# LPC11D14 register map
File version: 4
CPU: 
Registers are 32-bit, read-write, reset 0x0 unless marked. A register's access mark holds for its fields unless they carry their own. Offsets are from the block's base; [hi:lo] are bit positions; 'fields as' and 'values as' point back to an identical list.

## IOCON — Product name title=UM10398 Chapter title=LPC111x/LPC11Cxx I/O configuration (IOCONFIG) Modification date=9/19/2011 Major revision=7 Minor revision=not available
Base 0x40044000
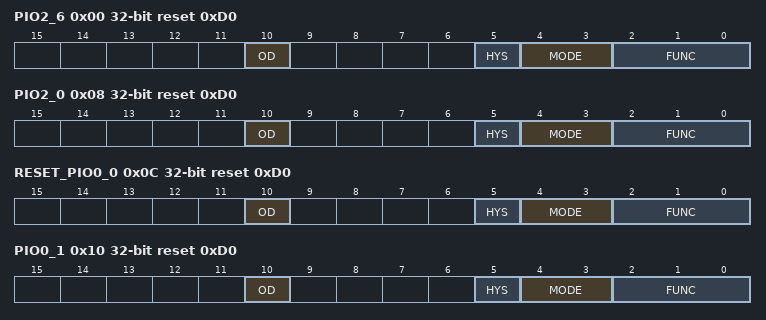
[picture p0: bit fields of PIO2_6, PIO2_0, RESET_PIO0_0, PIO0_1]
0x00 PIO2_6 reset 0xD0 — I/O configuration for pin PIO2_6
  [10] OD — Selects pseudo open-drain mode. See Section 7.1 for part specific details.
    0=STANDARD_GPIO_OUTPUT; 1=OPEN_DRAIN_OUTPUT
  [5] HYS — Hysteresis.
    0=DISABLE_; 1=ENABLE_
  [4:3] MODE — Selects function mode (on-chip pull-up/pull-down resistor control).
    0=INACTIVE_NO_PULL_DO (Inactive (no pull-down/pull-up resistor enabled).); 1=PULL_DOWN_RESISTOR_E (Pull-down resistor enabled.); 2=PULL_UP_RESISTOR_ENA (Pull-up resistor enabled.); 3=REPEATER_MODE_
  [2:0] FUNC — Selects pin function. All other values are reserved.
    0=SELECTS_FUNCTION_PIO (Selects function PIO2_6.)
0x08 PIO2_0 reset 0xD0 — I/O configuration for pin PIO2_0/DTR/SSEL1
  [10] OD — Selects pseudo open-drain mode. See Section 7.1 for part specific details.
    0=STANDARD_GPIO_OUTPUT; 1=OPEN_DRAIN_OUTPUT
  [5] HYS — Hysteresis.
    0=DISABLE_; 1=ENABLE_
  [4:3] MODE — Selects function mode (on-chip pull-up/pull-down resistor control).
    values as PIO2_6.MODE
  [2:0] FUNC — Selects pin function. All other values are reserved.
    0=SELECTS_FUNCTION_PIO (Selects function PIO2_0.); 1=SELECT_FUNCTION_DTR_; 2=SELECT_FUNCTION_SSEL (Select function SSEL1.)
0x0C RESET_PIO0_0 reset 0xD0 — I/O configuration for pin RESET/PIO0_0
  [10] OD — Selects pseudo open-drain mode. See Section 7.1 for part specific details.
    0=STANDARD_GPIO_OUTPUT; 1=OPEN_DRAIN_OUTPUT
  [5] HYS — Hysteresis.
    0=DISABLE_; 1=ENABLE_
  [4:3] MODE — Selects function mode (on-chip pull-up/pull-down resistor control).
    values as PIO2_6.MODE
  [2:0] FUNC — Selects pin function. All other values are reserved.
    0=SELECTS_FUNCTION_RES (Selects function RESET.); 1=SELECTS_FUNCTION_PIO (Selects function PIO0_0.)
0x10 PIO0_1 reset 0xD0 — I/O configuration for pin PIO0_1/CLKOUT/CT32B0_MAT2
  [10] OD — Selects pseudo open-drain mode. See Section 7.1 for part specific details.
    0=STANDARD_GPIO_OUTPUT; 1=OPEN_DRAIN_OUTPUT
  [5] HYS — Hysteresis.
    0=DISABLE_; 1=ENABLE_
  [4:3] MODE — Selects function mode (on-chip pull-up/pull-down resistor control).
    values as PIO2_6.MODE
  [2:0] FUNC — Selects pin function. All other values are reserved.
    0=SELECTS_FUNCTION_PIO (Selects function PIO0_1.); 1=SELECTS_FUNCTION_CLK (Selects function CLKOUT.); 2=SELECTS_FUNCTION_CT3 (Selects function CT32B0_MAT2.)
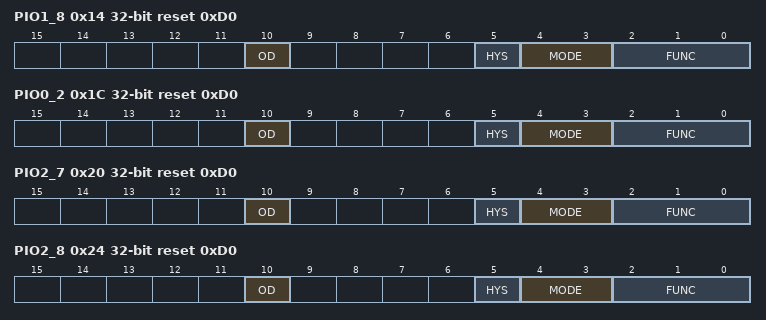
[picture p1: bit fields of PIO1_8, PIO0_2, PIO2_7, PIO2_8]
0x14 PIO1_8 reset 0xD0 — I/O configuration for pin PIO1_8/CT16B1_CAP0
  [10] OD — Selects pseudo open-drain mode. See Section 7.1 for part specific details.
    0=STANDARD_GPIO_OUTPUT; 1=OPEN_DRAIN_OUTPUT
  [5] HYS — Hysteresis.
    0=DISABLE_; 1=ENABLE_
  [4:3] MODE — Selects function mode (on-chip pull-up/pull-down resistor control).
    values as PIO2_6.MODE
  [2:0] FUNC — Selects pin function. All other values are reserved.
    0=SELECTS_FUNCTION_PIO (Selects function PIO1_8.); 1=SELECTS_FUNCTION_CT1 (Selects function CT16B1_CAP0.)
0x1C PIO0_2 reset 0xD0 — I/O configuration for pin PIO0_2/SSEL0/CT16B0_CAP0
  [10] OD — Selects pseudo open-drain mode. See Section 7.1 for part specific details.
    0=STANDARD_GPIO_OUTPUT; 1=OPEN_DRAIN_OUTPUT
  [5] HYS — Hysteresis.
    0=DISABLE_; 1=ENABLE_
  [4:3] MODE — Selects function mode (on-chip pull-up/pull-down resistor control).
    values as PIO2_6.MODE
  [2:0] FUNC — Selects pin function. All other values are reserved.
    0=SELECTS_FUNCTION_PIO (Selects function PIO0_2.); 1=SELECTS_FUNCTION_SSE (Selects function SSEL0.); 2=SELECTS_FUNCTION_CT1 (Selects function CT16B0_CAP0.)
0x20 PIO2_7 reset 0xD0 — I/O configuration for pin PIO2_7
  [10] OD — Selects pseudo open-drain mode. See Section 7.1 for part specific details.
    0=STANDARD_GPIO_OUTPUT; 1=OPEN_DRAIN_OUTPUT
  [5] HYS — Hysteresis.
    0=DISABLE_; 1=ENABLE_
  [4:3] MODE — Selects function mode (on-chip pull-up/pull-down resistor control).
    values as PIO2_6.MODE
  [2:0] FUNC — Selects pin function. All other values are reserved.
    0=SELECTS_FUNCTION_PIO (Selects function PIO2_7.)
0x24 PIO2_8 reset 0xD0 — I/O configuration for pin PIO2_8
  [10] OD — Selects pseudo open-drain mode. See Section 7.1 for part specific details.
    0=STANDARD_GPIO_OUTPUT; 1=OPEN_DRAIN_OUTPUT
  [5] HYS — Hysteresis.
    0=DISABLE_; 1=ENABLE_
  [4:3] MODE — Selects function mode (on-chip pull-up/pull-down resistor control).
    values as PIO2_6.MODE
  [2:0] FUNC — Selects pin function. All other values are reserved.
    0=SELECTS_FUNCTION_PIO (Selects function PIO2_8.)
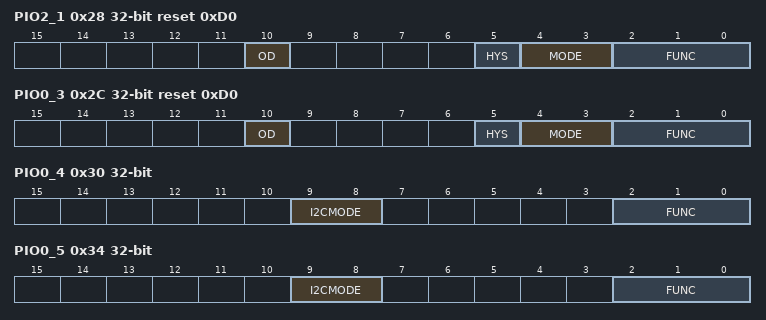
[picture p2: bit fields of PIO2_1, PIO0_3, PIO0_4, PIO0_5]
0x28 PIO2_1 reset 0xD0 — I/O configuration for pin PIO2_1/DSR/SCK1
  [10] OD — Selects pseudo open-drain mode. See Section 7.1 for part specific details.
    0=STANDARD_GPIO_OUTPUT; 1=OPEN_DRAIN_OUTPUT
  [5] HYS — Hysteresis.
    0=DISABLE_; 1=ENABLE_
  [4:3] MODE — Selects function mode (on-chip pull-up/pull-down resistor control).
    values as PIO2_6.MODE
  [2:0] FUNC — Selects pin function. All other values are reserved.
    0=SELECTS_FUNCTION_PIO (Selects function PIO2_1.); 1=SELECT_FUNCTION_DSR_; 2=SELECT_FUNCTION_SCK1
0x2C PIO0_3 reset 0xD0 — I/O configuration for pin PIO0_3
  [10] OD — Selects pseudo open-drain mode.
    0=STANDARD_GPIO_OUTPUT; 1=OPEN_DRAIN_OUTPUT
  [5] HYS — Hysteresis.
    0=DISABLE_; 1=ENABLE_
  [4:3] MODE — Selects function mode (on-chip pull-up/pull-down resistor control).
    values as PIO2_6.MODE
  [2:0] FUNC — Selects pin function. All other values are reserved.
    0=SELECTS_FUNCTION_PIO (Selects function PIO0_3.)
0x30 PIO0_4 — I/O configuration for pin PIO0_4/SCL
  [9:8] I2CMODE — Selects I2C mode. Select Standard mode (I2CMODE = 00, default) or Standard I/O functionality (I2CMODE = 01) if the pin function is GPIO (FUNC = 000).
    0=STANDARD_MODE/_FAST_ (Standard mode/ Fast-mode I2C.); 1=STANDARD_I/O_FUNCTIO (Standard I/O functionality); 2=FAST_MODE_PLUS_I2C
  [2:0] FUNC — Selects pin function. All other values are reserved.
    0=SELECTS_FUNCTION_PIO (Selects function PIO0_4 (open-drain pin).); 1=SELECTS_I2C_FUNCTION (Selects I2C function SCL (open-drain pin).)
0x34 PIO0_5 — I/O configuration for pin PIO0_5/SDA
  [9:8] I2CMODE — Selects I2C mode. Select Standard mode (I2CMODE = 00, default) or Standard I/O functionality (I2CMODE = 01) if the pin function is GPIO (FUNC = 000).
    values as PIO0_4.I2CMODE
  [2:0] FUNC — Selects pin function. All other values are reserved.
    0=SELECTS_FUNCTION_PIO (Selects function PIO0_5 (open-drain pin).); 1=SELECTS_I2C_FUNCTION (Selects I2C function SDA (open-drain pin).)
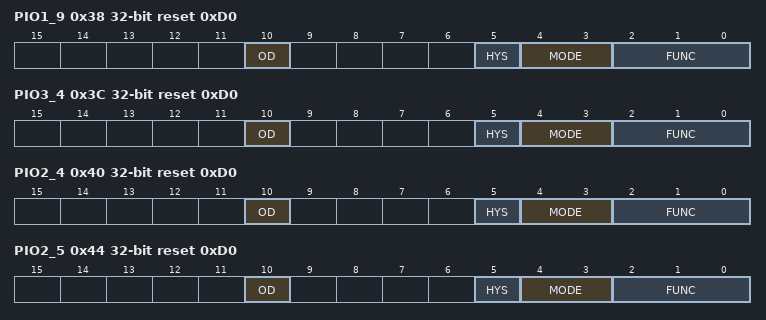
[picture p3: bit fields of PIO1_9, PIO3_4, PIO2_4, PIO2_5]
0x38 PIO1_9 reset 0xD0 — I/O configuration for pin PIO1_9/CT16B1_MAT0
  [10] OD — Selects pseudo open-drain mode. See Section 7.1 for part specific details.
    0=STANDARD_GPIO_OUTPUT; 1=OPEN_DRAIN_OUTPUT
  [5] HYS — Hysteresis.
    0=DISABLE_; 1=ENABLE_
  [4:3] MODE — Selects function mode (on-chip pull-up/pull-down resistor control).
    values as PIO2_6.MODE
  [2:0] FUNC — Selects pin function. All other values are reserved.
    0=SELECTS_FUNCTION_PIO (Selects function PIO1_9.); 1=SELECTS_FUNCTION_CT1 (Selects function CT16B1_MAT0.)
0x3C PIO3_4 reset 0xD0 — I/O configuration for pin PIO3_4
  [10] OD — Selects pseudo open-drain mode. See Section 7.1 for part specific details.
    0=STANDARD_GPIO_OUTPUT; 1=OPEN_DRAIN_OUTPUT
  [5] HYS — Hysteresis.
    0=DISABLE_; 1=ENABLE_
  [4:3] MODE — Selects function mode (on-chip pull-up/pull-down resistor control).
    values as PIO2_6.MODE
  [2:0] FUNC — Selects pin function. All other values are reserved.
    0=SELECTS_FUNCTION_PIO (Selects function PIO3_4.)
0x40 PIO2_4 reset 0xD0 — I/O configuration for pin PIO2_4
  [10] OD — Selects pseudo open-drain mode. See Section 7.1 for part specific details.
    0=STANDARD_GPIO_OUTPUT; 1=OPEN_DRAIN_OUTPUT
  [5] HYS — Hysteresis.
    0=DISABLE_; 1=ENABLE_
  [4:3] MODE — Selects function mode (on-chip pull-up/pull-down resistor control).
    values as PIO2_6.MODE
  [2:0] FUNC — Selects pin function. All other values are reserved.
    0=SELECTS_FUNCTION_PIO (Selects function PIO2_4.)
0x44 PIO2_5 reset 0xD0 — I/O configuration for pin PIO2_5
  [10] OD — Selects pseudo open-drain mode.
    0=STANDARD_GPIO_OUTPUT; 1=OPEN_DRAIN_OUTPUT
  [5] HYS — Hysteresis.
    0=DISABLE_; 1=ENABLE_
  [4:3] MODE — Selects function mode (on-chip pull-up/pull-down resistor control).
    values as PIO2_6.MODE
  [2:0] FUNC — Selects pin function. All other values are reserved.
    0=SELECTS_FUNCTION_PIO (Selects function PIO2_5.)
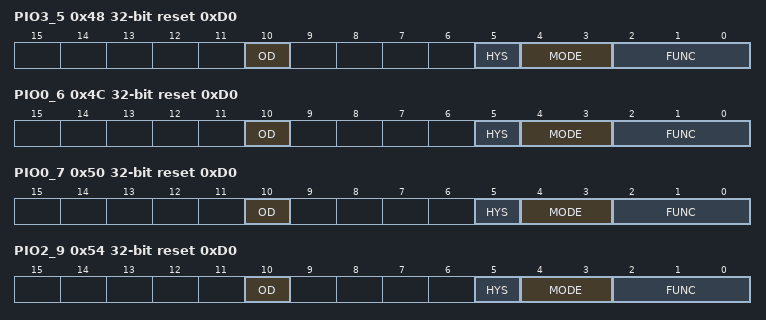
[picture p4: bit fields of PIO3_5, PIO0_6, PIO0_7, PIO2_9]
0x48 PIO3_5 reset 0xD0 — I/O configuration for pin PIO3_5
  [10] OD — Selects pseudo open-drain mode. See Section 7.1 for part specific details.
    0=STANDARD_GPIO_OUTPUT; 1=OPEN_DRAIN_OUTPUT
  [5] HYS — Hysteresis.
    0=DISABLE_; 1=ENABLE_
  [4:3] MODE — Selects function mode (on-chip pull-up/pull-down resistor control).
    values as PIO2_6.MODE
  [2:0] FUNC — Selects pin function. All other values are reserved.
    0=SELECTS_FUNCTION_PIO (Selects function PIO3_5.)
0x4C PIO0_6 reset 0xD0 — I/O configuration for pin PIO0_6/SCK0
  [10] OD — Selects pseudo open-drain mode. See Section 7.1 for part specific details.
    0=STANDARD_GPIO_OUTPUT; 1=OPEN_DRAIN_OUTPUT
  [5] HYS — Hysteresis.
    0=DISABLE_; 1=ENABLE_
  [4:3] MODE — Selects function mode (on-chip pull-up/pull-down resistor control).
    values as PIO2_6.MODE
  [2:0] FUNC — Selects pin function. All other values are reserved.
    0=SELECTS_FUNCTION_PIO (Selects function PIO0_6.); 2=SELECTS_FUNCTION_SCK (Selects function SCK0 (only if pin PIO0_6/SCK0 selected in Table 98).)
0x50 PIO0_7 reset 0xD0 — I/O configuration for pin PIO0_7/CTS
  [10] OD — Selects pseudo open-drain mode. See Section 7.1 for part specific details.
    0=STANDARD_GPIO_OUTPUT; 1=OPEN_DRAIN_OUTPUT
  [5] HYS — Hysteresis.
    0=DISABLE_; 1=ENABLE_
  [4:3] MODE — Selects function mode (on-chip pull-up/pull-down resistor control).
    values as PIO2_6.MODE
  [2:0] FUNC — Selects pin function. All other values are reserved.
    0=SELECTS_FUNCTION_PIO (Selects function PIO0_7.); 1=SELECT_FUNCTION_CTS_
0x54 PIO2_9 reset 0xD0 — I/O configuration for pin PIO2_9
  [10] OD — Selects pseudo open-drain mode. See Section 7.1 for part specific details.
    0=STANDARD_GPIO_OUTPUT; 1=OPEN_DRAIN_OUTPUT
  [5] HYS — Hysteresis.
    0=DISABLE_; 1=ENABLE_
  [4:3] MODE — Selects function mode (on-chip pull-up/pull-down resistor control).
    values as PIO2_6.MODE
  [2:0] FUNC — Selects pin function. All other values are reserved.
    0=SELECTS_FUNCTION_PIO (Selects function PIO2_9.)
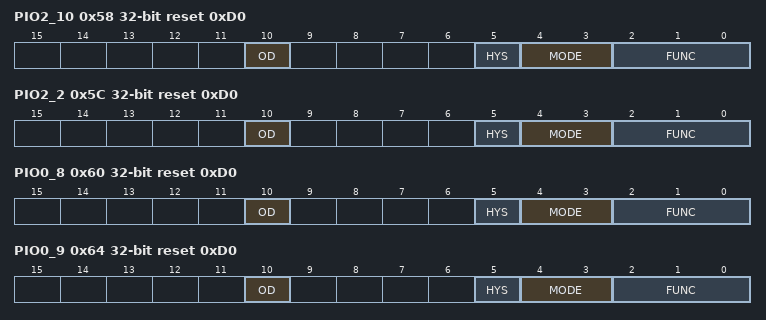
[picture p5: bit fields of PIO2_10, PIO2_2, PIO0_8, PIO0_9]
0x58 PIO2_10 reset 0xD0 — I/O configuration for pin PIO2_10
  [10] OD — Selects pseudo open-drain mode. See Section 7.1 for part specific details.
    0=STANDARD_GPIO_OUTPUT; 1=OPEN_DRAIN_OUTPUT
  [5] HYS — Hysteresis.
    0=DISABLE_; 1=ENABLE_
  [4:3] MODE — Selects function mode (on-chip pull-up/pull-down resistor control).
    values as PIO2_6.MODE
  [2:0] FUNC — Selects pin function. All other values are reserved.
    0=SELECTS_FUNCTION_PIO (Selects function PIO2_10.)
0x5C PIO2_2 reset 0xD0 — I/O configuration for pin PIO2_2/DCD/MISO1
  [10] OD — Selects pseudo open-drain mode.
    0=STANDARD_GPIO_OUTPUT; 1=OPEN_DRAIN_OUTPUT
  [5] HYS — Hysteresis.
    0=DISABLE_; 1=ENABLE_
  [4:3] MODE — Selects function mode (on-chip pull-up/pull-down resistor control).
    values as PIO2_6.MODE
  [2:0] FUNC — Selects pin function. All other values are reserved.
    0=SELECTS_FUNCTION_PIO (Selects function PIO2_2.); 1=SELECT_FUNCTION_DCD_; 2=SELECT_FUNCTION_MISO (Select function MISO1.)
0x60 PIO0_8 reset 0xD0 — I/O configuration for pin PIO0_8/MISO0/CT16B0_MAT0
  [10] OD — Selects pseudo open-drain mode. See Section 7.1 for part specific details.
    0=STANDARD_GPIO_OUTPUT; 1=OPEN_DRAIN_OUTPUT
  [5] HYS — Hysteresis.
    0=DISABLE_; 1=ENABLE_
  [4:3] MODE — Selects function mode (on-chip pull-up/pull-down resistor control).
    values as PIO2_6.MODE
  [2:0] FUNC — Selects pin function. All other values are reserved.
    0=SELECTS_FUNCTION_PIO (Selects function PIO0_8.); 1=SELECTS_FUNCTION_MIS (Selects function MISO0.); 2=SELECTS_FUNCTION_CT1 (Selects function CT16B0_MAT0.)
0x64 PIO0_9 reset 0xD0 — I/O configuration for pin PIO0_9/MOSI0/CT16B0_MAT1
  [10] OD — Selects pseudo open-drain mode. See Section 7.1 for part specific details.
    0=STANDARD_GPIO_OUTPUT; 1=OPEN_DRAIN_OUTPUT
  [5] HYS — Hysteresis.
    0=DISABLE_; 1=ENABLE_
  [4:3] MODE — Selects function mode (on-chip pull-up/pull-down resistor control).
    values as PIO2_6.MODE
  [2:0] FUNC — Selects pin function. All other values are reserved.
    0=SELECTS_FUNCTION_PIO (Selects function PIO0_9.); 1=SELECTS_FUNCTION_MOS (Selects function MOSI0.); 2=SELECTS_FUNCTION_CT1 (Selects function CT16B0_MAT1.)
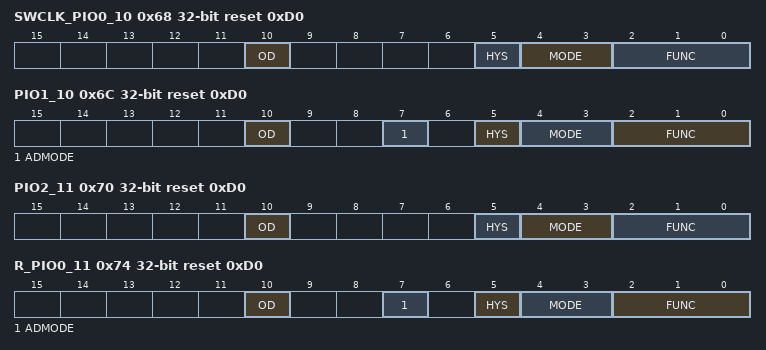
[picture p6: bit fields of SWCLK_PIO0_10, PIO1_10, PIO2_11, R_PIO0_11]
0x68 SWCLK_PIO0_10 reset 0xD0 — I/O configuration for pin SWCLK/PIO0_10/ SCK0/CT16B0_MAT2
  [10] OD — Selects pseudo open-drain mode.
    0=STANDARD_GPIO_OUTPUT; 1=OPEN_DRAIN_OUTPUT
  [5] HYS — Hysteresis.
    0=DISABLE_; 1=ENABLE_
  [4:3] MODE — Selects function mode (on-chip pull-up/pull-down resistor control).
    values as PIO2_6.MODE
  [2:0] FUNC — Selects pin function. All other values are reserved.
    0=SELECTS_FUNCTION_SWC (Selects function SWCLK.); 1=SELECTS_FUNCTION_PIO (Selects function PIO0_10.); 2=SELECTS_FUNCTION_SCK (Selects function SCK0 (only if pin SWCLK/PIO0_10/SCK0/CT16B0_MAT2 selected in Table 98).); 3=SELECTS_FUNCTION_CT1 (Selects function CT16B0_MAT2.)
0x6C PIO1_10 reset 0xD0 — I/O configuration for pin PIO1_10/AD6/CT16B1_MAT1
  [10] OD — Selects pseudo open-drain mode. See Section 7.1 for part specific details.
    0=STANDARD_GPIO_OUTPUT; 1=OPEN_DRAIN_OUTPUT
  [7] ADMODE — Selects Analog/Digital mode
    0=ANALOG_INPUT_MODE; 1=DIGITAL_FUNCTIONAL_M (Digital functional mode)
  [5] HYS — Hysteresis.
    0=DISABLE_; 1=ENABLE_
  [4:3] MODE — Selects function mode (on-chip pull-up/pull-down resistor control).
    values as PIO2_6.MODE
  [2:0] FUNC — Selects pin function. All other values are reserved.
    0=SELECTS_FUNCTION_PIO (Selects function PIO1_10.); 1=SELECTS_FUNCTION_AD6; 2=SELECTS_FUNCTION_CT1 (Selects function CT16B1_MAT1.)
0x70 PIO2_11 reset 0xD0 — I/O configuration for pin PIO2_11/SCK0
  [10] OD — Selects pseudo open-drain mode. See Section 7.1 for part specific details.
    0=STANDARD_GPIO_OUTPUT; 1=OPEN_DRAIN_OUTPUT
  [5] HYS — Hysteresis.
    0=DISABLE_; 1=ENABLE_
  [4:3] MODE — Selects function mode (on-chip pull-up/pull-down resistor control).
    values as PIO2_6.MODE
  [2:0] FUNC — Selects pin function. All other values are reserved.
    0=SELECTS_FUNCTION_PIO (Selects function PIO2_11.); 1=SELECT_FUNCTION_SCK0 (Select function SCK0 (only if pin PIO2_11/SCK0 selected in Table 98).)
0x74 R_PIO0_11 reset 0xD0 — I/O configuration for pin R/PIO0_11/AD0/CT32B0_MAT3
  [10] OD — Selects pseudo open-drain mode.
    0=STANDARD_GPIO_OUTPUT; 1=OPEN_DRAIN_OUTPUT
  [7] ADMODE — Selects Analog/Digital mode
    values as PIO1_10.ADMODE
  [5] HYS — Hysteresis.
    0=DISABLE_; 1=ENABLE_
  [4:3] MODE — Selects function mode (on-chip pull-up/pull-down resistor control).
    values as PIO2_6.MODE
  [2:0] FUNC — Selects pin function. All other values are reserved.
    0=SELECTS_FUNCTION_R_ (Selects function R. This function is reserved. Select one of the alternate functions below.); 1=SELECTS_FUNCTION_PIO (Selects function PIO0_11.); 2=SELECTS_FUNCTION_AD0; 3=SELECTS_FUNCTION_CT3 (Selects function CT32B0_MAT3.)
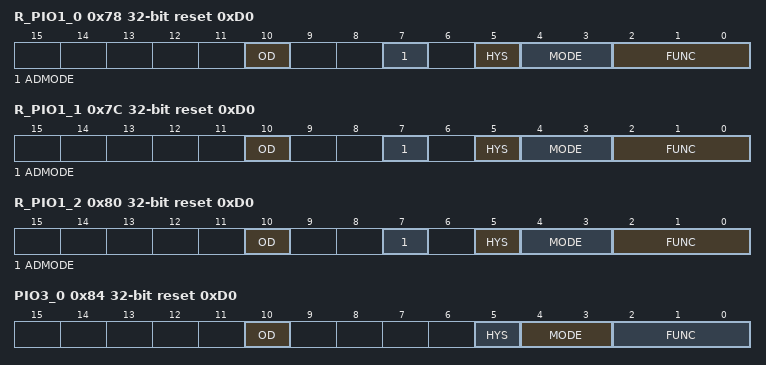
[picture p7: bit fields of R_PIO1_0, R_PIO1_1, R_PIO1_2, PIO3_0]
0x78 R_PIO1_0 reset 0xD0 — I/O configuration for pin R/PIO1_0/AD1/CT32B1_CAP0
  [10] OD — Selects pseudo open-drain mode. See Section 7.1 for part specific details.
    0=STANDARD_GPIO_OUTPUT; 1=OPEN_DRAIN_OUTPUT
  [7] ADMODE — Selects Analog/Digital mode
    values as PIO1_10.ADMODE
  [5] HYS — Hysteresis.
    0=DISABLE_; 1=ENABLE_
  [4:3] MODE — Selects function mode (on-chip pull-up/pull-down resistor control).
    values as PIO2_6.MODE
  [2:0] FUNC — Selects pin function. All other values are reserved.
    0=SELECTS_FUNCTION_R_ (Selects function R. This function is reserved. Select one of the alternate functions below.); 1=SELECTS_FUNCTION_PIO (Selects function PIO1_0.); 2=SELECTS_FUNCTION_AD1; 3=SELECTS_FUNCTION_CT3 (Selects function CT32B1_CAP0.)
0x7C R_PIO1_1 reset 0xD0 — I/O configuration for pin R/PIO1_1/AD2/CT32B1_MAT0
  [10] OD — Selects pseudo open-drain mode. See Section 7.1 for part specific details.
    0=STANDARD_GPIO_OUTPUT; 1=OPEN_DRAIN_OUTPUT
  [7] ADMODE — Selects Analog/Digital mode
    values as PIO1_10.ADMODE
  [5] HYS — Hysteresis.
    0=DISABLE_; 1=ENABLE_
  [4:3] MODE — Selects function mode (on-chip pull-up/pull-down resistor control).
    values as PIO2_6.MODE
  [2:0] FUNC — Selects pin function. All other values are reserved.
    0=SELECTS_FUNCTION_R_ (Selects function R. This function is reserved. Select one of the alternate functions below.); 1=SELECTS_FUNCTION_PIO (Selects function PIO1_1.); 2=SELECTS_FUNCTION_AD2; 3=SELECTS_FUNCTION_CT3 (Selects function CT32B1_MAT0.)
0x80 R_PIO1_2 reset 0xD0 — I/O configuration for pin R/PIO1_2/AD3/CT32B1_MAT1
  [10] OD — Selects pseudo open-drain mode. See Section 7.1 for part specific details.
    0=STANDARD_GPIO_OUTPUT; 1=OPEN_DRAIN_OUTPUT
  [7] ADMODE — Selects Analog/Digital mode
    values as PIO1_10.ADMODE
  [5] HYS — Hysteresis.
    0=DISABLE_; 1=ENABLE_
  [4:3] MODE — Selects function mode (on-chip pull-up/pull-down resistor control).
    values as PIO2_6.MODE
  [2:0] FUNC — Selects pin function. All other values are reserved.
    0=SELECTS_FUNCTION_R_ (Selects function R. This function is reserved. Select one of the alternate functions below.); 1=SELECTS_FUNCTION_PIO (Selects function PIO1_2.); 2=SELECTS_FUNCTION_AD3; 3=SELECTS_FUNCTION_CT3 (Selects function CT32B1_MAT1.)
0x84 PIO3_0 reset 0xD0 — I/O configuration for pin PIO3_0/DTR
  [10] OD — Selects pseudo open-drain mode.
    0=STANDARD_GPIO_OUTPUT; 1=OPEN_DRAIN_OUTPUT
  [5] HYS — Hysteresis.
    0=DISABLE_; 1=ENABLE_
  [4:3] MODE — Selects function mode (on-chip pull-up/pull-down resistor control).
    values as PIO2_6.MODE
  [2:0] FUNC — Selects pin function. All other values are reserved.
    0=SELECTS_FUNCTION_PIO (Selects function PIO3_0.); 1=SELECTS_FUNCTION_DTR
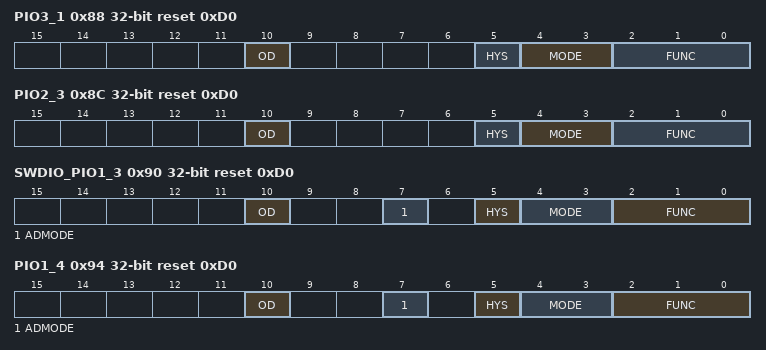
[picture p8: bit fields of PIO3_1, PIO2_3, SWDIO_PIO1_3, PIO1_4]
0x88 PIO3_1 reset 0xD0 — I/O configuration for pin PIO3_1/DSR
  [10] OD — Selects pseudo open-drain mode. See Section 7.1 for part specific details.
    0=STANDARD_GPIO_OUTPUT; 1=OPEN_DRAIN_OUTPUT
  [5] HYS — Hysteresis.
    0=DISABLE_; 1=ENABLE_
  [4:3] MODE — Selects function mode (on-chip pull-up/pull-down resistor control).
    values as PIO2_6.MODE
  [2:0] FUNC — Selects pin function. All other values are reserved.
    0=SELECTS_FUNCTION_PIO (Selects function PIO3_1.); 1=SELECTS_FUNCTION_DSR
0x8C PIO2_3 reset 0xD0 — I/O configuration for pin PIO2_3/RI/MOSI1
  [10] OD — Selects pseudo open-drain mode. See Section 7.1 for part specific details.
    0=STANDARD_GPIO_OUTPUT; 1=OPEN_DRAIN_OUTPUT
  [5] HYS — Hysteresis.
    0=DISABLE_; 1=ENABLE_
  [4:3] MODE — Selects function mode (on-chip pull-up/pull-down resistor control).
    values as PIO2_6.MODE
  [2:0] FUNC — Selects pin function. All other values are reserved.
    0=SELECTS_FUNCTION_PIO (Selects function PIO2_3.); 1=SELECTS_FUNCTION_RI_; 2=SELECTS_FUNCTION_MOS (Selects function MOSI1.)
0x90 SWDIO_PIO1_3 reset 0xD0 — I/O configuration for pin SWDIO/PIO1_3/AD4/CT32B1_MAT2
  [10] OD — Selects pseudo open-drain mode.
    0=STANDARD_GPIO_OUTPUT; 1=OPEN_DRAIN_OUTPUT
  [7] ADMODE — Selects Analog/Digital mode
    values as PIO1_10.ADMODE
  [5] HYS — Hysteresis.
    0=DISABLE_; 1=ENABLE_
  [4:3] MODE — Selects function mode (on-chip pull-up/pull-down resistor control).
    values as PIO2_6.MODE
  [2:0] FUNC — Selects pin function. All other values are reserved.
    0=SELECTS_FUNCTION_SWD (Selects function SWDIO.); 1=SELECTS_FUNCTION_PIO (Selects function PIO1_3.); 2=SELECTS_FUNCTION_AD4; 3=SELECTS_FUNCTION_CT3 (Selects function CT32B1_MAT2.)
0x94 PIO1_4 reset 0xD0 — I/O configuration for pin PIO1_4/AD5/CT32B1_MAT3
  [10] OD — Selects pseudo open-drain mode. See Section 7.1 for part specific details.
    0=STANDARD_GPIO_OUTPUT; 1=OPEN_DRAIN_OUTPUT
  [7] ADMODE — Selects Analog/Digital mode
    values as PIO1_10.ADMODE
  [5] HYS — Hysteresis.
    0=DISABLE_; 1=ENABLE_
  [4:3] MODE — Selects function mode (on-chip pull-up/pull-down resistor control).
    values as PIO2_6.MODE
  [2:0] FUNC — Selects pin function. This pin functions as WAKEUP pin if the LPC111x/LPC11Cxx is in Deep power-down mode regardless of the value of FUNC. All other values are reserved.
    0=SELECTS_FUNCTION_PIO (Selects function PIO1_4.); 1=SELECTS_FUNCTION_AD5; 2=SELECTS_FUNCTION_CT3 (Selects function CT32B1_MAT3.)
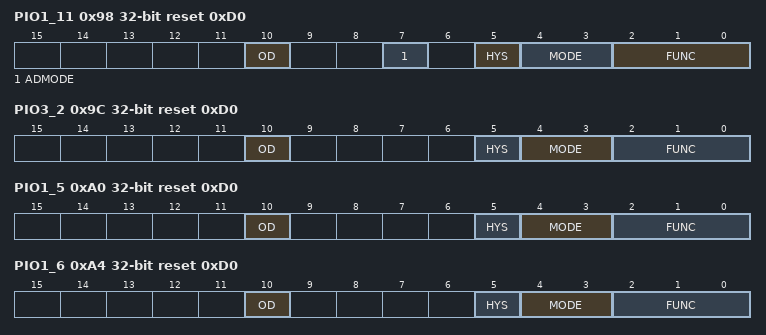
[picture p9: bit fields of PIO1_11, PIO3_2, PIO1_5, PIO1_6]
0x98 PIO1_11 reset 0xD0 — I/O configuration for pin PIO1_11/AD7
  [10] OD — Selects pseudo open-drain mode. See Section 7.1 for part specific details.
    0=STANDARD_GPIO_OUTPUT; 1=OPEN_DRAIN_OUTPUT
  [7] ADMODE — Selects Analog/Digital mode
    values as PIO1_10.ADMODE
  [5] HYS — Hysteresis.
    0=DISABLE_; 1=ENABLE_
  [4:3] MODE — Selects function mode (on-chip pull-up/pull-down resistor control).
    values as PIO2_6.MODE
  [2:0] FUNC — Selects pin function. All other values are reserved.
    0=SELECTS_FUNCTION_PIO (Selects function PIO1_11.); 1=SELECTS_FUNCTION_AD7
0x9C PIO3_2 reset 0xD0 — I/O configuration for pin PIO3_2/DCD
  [10] OD — Selects pseudo open-drain mode.
    0=STANDARD_GPIO_OUTPUT; 1=OPEN_DRAIN_OUTPUT
  [5] HYS — Hysteresis.
    0=DISABLE_; 1=ENABLE_
  [4:3] MODE — Selects function mode (on-chip pull-up/pull-down resistor control).
    values as PIO2_6.MODE
  [2:0] FUNC — Selects pin function. All other values are reserved.
    0=SELECTS_FUNCTION_PIO (Selects function PIO3_2.); 1=SELECTS_FUNCTION_DCD
0xA0 PIO1_5 reset 0xD0 — I/O configuration for pin PIO1_5/RTS/CT32B0_CAP0
  [10] OD — Selects pseudo open-drain mode. See Section 7.1 for part specific details.
    0=STANDARD_GPIO_OUTPUT; 1=OPEN_DRAIN_OUTPUT
  [5] HYS — Hysteresis.
    0=DISABLE_; 1=ENABLE_
  [4:3] MODE — Selects function mode (on-chip pull-up/pull-down resistor control).
    values as PIO2_6.MODE
  [2:0] FUNC — Selects pin function. All other values are reserved.
    0=SELECTS_FUNCTION_PIO (Selects function PIO1_5.); 1=SELECTS_FUNCTION_RTS; 2=SELECTS_FUNCTION_CT3 (Selects function CT32B0_CAP0.)
0xA4 PIO1_6 reset 0xD0 — I/O configuration for pin PIO1_6/RXD/CT32B0_MAT0
  [10] OD — Selects pseudo open-drain mode. See Section 7.1 for part specific details.
    0=STANDARD_GPIO_OUTPUT; 1=OPEN_DRAIN_OUTPUT
  [5] HYS — Hysteresis.
    0=DISABLE_; 1=ENABLE_
  [4:3] MODE — Selects function mode (on-chip pull-up/pull-down resistor control).
    values as PIO2_6.MODE
  [2:0] FUNC — Selects pin function. All other values are reserved.
    0=SELECTS_FUNCTION_PIO (Selects function PIO1_6.); 1=SELECTS_FUNCTION_RXD; 2=SELECTS_FUNCTION_CT3 (Selects function CT32B0_MAT0.)
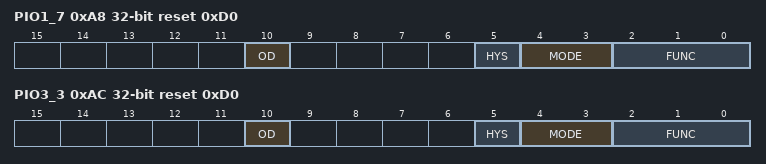
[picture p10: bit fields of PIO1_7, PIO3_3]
0xA8 PIO1_7 reset 0xD0 — I/O configuration for pin PIO1_7/TXD/CT32B0_MAT1
  [10] OD — Selects pseudo open-drain mode. See Section 7.1 for part specific details.
    0=STANDARD_GPIO_OUTPUT; 1=OPEN_DRAIN_OUTPUT
  [5] HYS — Hysteresis.
    0=DISABLE_; 1=ENABLE_
  [4:3] MODE — Selects function mode (on-chip pull-up/pull-down resistor control).
    values as PIO2_6.MODE
  [2:0] FUNC — Selects pin function. All other values are reserved.
    0=SELECTS_FUNCTION_PIO (Selects function PIO1_7.); 1=SELECTS_FUNCTION_TXD; 2=SELECTS_FUNCTION_CT3 (Selects function CT32B0_MAT1.)
0xAC PIO3_3 reset 0xD0 — I/O configuration for pin PIO3_3/RI
  [10] OD — Selects pseudo open-drain mode. See Section 7.1 for part specific details.
    0=STANDARD_GPIO_OUTPUT; 1=OPEN_DRAIN_OUTPUT
  [5] HYS — Hysteresis.
    0=DISABLE_; 1=ENABLE_
  [4:3] MODE — Selects function mode (on-chip pull-up/pull-down resistor control).
    values as PIO2_6.MODE
  [2:0] FUNC — Selects pin function. All other values are reserved.
    0=SELECTS_FUNCTION_PIO (Selects function PIO3_3.); 1=SELECTS_FUNCTION_RI_
0xB0 SCK_LOC — SCK pin location select register
  [1:0] SCKLOC — Selects pin location for SCK0 pin.
    0=PIO0_10 (Selects SCK0 function in pin location SWCLK/PIO0_10/SCK0/CT16B0_MAT2 (see Table 80).); 1=PIO2_11 (Selects SCK0 function in pin location PIO2_11/SCK0 (see Table 82.); 2=PIO0_6 (Selects SCK0 function in pin location PIO0_6/SCK0 (see Table 73).)
0xB4 DSR_LOC — DSR pin location select register
  [1:0] DSRLOC — Selects pin location for DSR0 pin.
    0=PIO2_1 (Selects DSR function in pin location PIO2_1/DSR/SCK1.); 1=PIO3_1 (Selects DSR function in pin location PIO3_1/DSR.)
0xB8 DCD_LOC — DCD pin location select register
  [1:0] DCDLOC — Selects pin location for DCD pin.
    0=PIO2_2 (Selects DCD function in pin location PIO2_2/DCD/MISO1.); 1=PIO3_2 (Selects DCD function in pin location PIO3_2/DCD.)
0xBC RI_LOC — RI pin location register
  [1:0] RILOC — Selects pin location for RI pin.
    0=PIO2_3 (Selects RI function in pin location PIO2_3/RI/MOSI1.); 1=PIO3_3 (Selects RI function in pin location PIO3_3/RI.)
